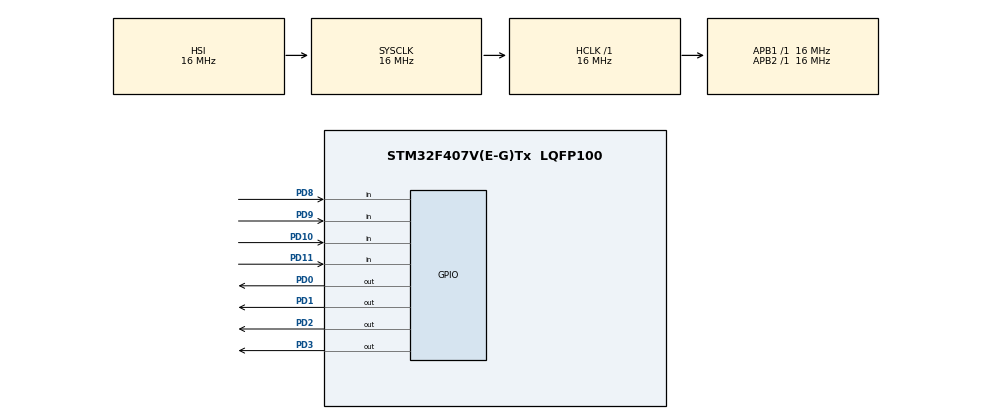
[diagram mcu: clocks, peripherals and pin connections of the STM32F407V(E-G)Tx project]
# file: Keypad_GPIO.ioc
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Mcu.Family=STM32F4
Mcu.Name=STM32F407V(E-G)Tx
Mcu.Package=LQFP100
NVIC.PriorityGroup=NVIC_PRIORITYGROUP_0
PD0.Signal=GPIO_Output
PD1.Signal=GPIO_Output
PD10.GPIO_PuPd=GPIO_PULLUP
PD10.Signal=GPIO_Input
PD11.GPIO_PuPd=GPIO_PULLUP
PD11.Signal=GPIO_Input
PD2.Signal=GPIO_Output
PD3.Signal=GPIO_Output
PD8.GPIO_PuPd=GPIO_PULLUP
PD8.Signal=GPIO_Input
PD9.GPIO_PuPd=GPIO_PULLUP
PD9.Signal=GPIO_Input
ProjectManager.HeapSize=0x200
ProjectManager.StackSize=0x400
ProjectManager.TargetToolchain=STM32CubeIDE
RCC.48MHZClocksFreq_Value=14285714.285714285
RCC.AHBFreq_Value=16000000
RCC.APB1Freq_Value=16000000
RCC.APB1TimFreq_Value=16000000
RCC.APB2Freq_Value=16000000
RCC.APB2TimFreq_Value=16000000
RCC.CortexFreq_Value=16000000
RCC.HCLKFreq_Value=16000000
RCC.HSE_VALUE=8000000
RCC.HSI_VALUE=16000000
RCC.LSE_VALUE=32768
RCC.PLLM=8
RCC.PLLN=50
RCC.PLLP=RCC_PLLP_DIV4
RCC.PLLQ=7
RCC.SYSCLKFreq_VALUE=16000000
RCC.VCOOutputFreq_Value=100000000
board=STM32F407G-DISC1

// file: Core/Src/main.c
/* USER CODE BEGIN Header */
/**
  ******************************************************************************
  * @file           : main.c
  * @brief          : Main program body
  ******************************************************************************
  * @attention
  *
  * Copyright (c) 2023 STMicroelectronics.
  * All rights reserved.
  *
  * This software is licensed under terms that can be found in the LICENSE file
  * in the root directory of this software component.
  * If no LICENSE file comes with this software, it is provided AS-IS.
  *
  ******************************************************************************
  */
/* USER CODE END Header */
#include "main.h"

/* USER CODE BEGIN Includes */
#include "keypad.h"
#include <stdio.h>
/* USER CODE END Includes */

/* USER CODE BEGIN PV */
uint8_t key = 0;
/* USER CODE END PV */

void SystemClock_Config(void);
static void MX_GPIO_Init(void);
/* USER CODE BEGIN PFP */

Keypad_HandleTypeDef keypad_init(void);

/* USER CODE END PFP */

int main(void)
{

  /* MCU Configuration--------------------------------------------------------*/

  /* Reset of all peripherals, Initializes the Flash interface and the Systick. */
  HAL_Init();

  /* Configure the system clock */
  SystemClock_Config();

  /* Initialize all configured peripherals */
  MX_GPIO_Init();
  /* USER CODE BEGIN 2 */

  Keypad_HandleTypeDef keypad = keypad_init();

  /* USER CODE END 2 */

  /* Infinite loop */
  /* USER CODE BEGIN WHILE */
  while (1)
  {

	  while(!key_selected(&keypad, &key));

    /* USER CODE END WHILE */

  }
}

void SystemClock_Config(void)
{
  RCC_OscInitTypeDef RCC_OscInitStruct = {0};
  RCC_ClkInitTypeDef RCC_ClkInitStruct = {0};

  /** Configure the main internal regulator output voltage
  */
  __HAL_RCC_PWR_CLK_ENABLE();
  __HAL_PWR_VOLTAGESCALING_CONFIG(PWR_REGULATOR_VOLTAGE_SCALE1);

  /** Initializes the RCC Oscillators according to the specified parameters
  * in the RCC_OscInitTypeDef structure.
  */
  RCC_OscInitStruct.OscillatorType = RCC_OSCILLATORTYPE_HSI;
  RCC_OscInitStruct.HSIState = RCC_HSI_ON;
  RCC_OscInitStruct.HSICalibrationValue = RCC_HSICALIBRATION_DEFAULT;
  RCC_OscInitStruct.PLL.PLLState = RCC_PLL_NONE;
  if (HAL_RCC_OscConfig(&RCC_OscInitStruct) != HAL_OK)
  {
    Error_Handler();
  }

  /** Initializes the CPU, AHB and APB buses clocks
  */
  RCC_ClkInitStruct.ClockType = RCC_CLOCKTYPE_HCLK|RCC_CLOCKTYPE_SYSCLK
                              |RCC_CLOCKTYPE_PCLK1|RCC_CLOCKTYPE_PCLK2;
  RCC_ClkInitStruct.SYSCLKSource = RCC_SYSCLKSOURCE_HSI;
  RCC_ClkInitStruct.AHBCLKDivider = RCC_SYSCLK_DIV1;
  RCC_ClkInitStruct.APB1CLKDivider = RCC_HCLK_DIV1;
  RCC_ClkInitStruct.APB2CLKDivider = RCC_HCLK_DIV1;

  if (HAL_RCC_ClockConfig(&RCC_ClkInitStruct, FLASH_LATENCY_0) != HAL_OK)
  {
    Error_Handler();
  }
}

static void MX_GPIO_Init(void)
{
  GPIO_InitTypeDef GPIO_InitStruct = {0};

  /* GPIO Ports Clock Enable */
  __HAL_RCC_GPIOD_CLK_ENABLE();

  /*Configure GPIO pin Output Level */
  HAL_GPIO_WritePin(GPIOD, GPIO_PIN_0|GPIO_PIN_1|GPIO_PIN_2|GPIO_PIN_3, GPIO_PIN_RESET);

  /*Configure GPIO pins : PD8 PD9 PD10 PD11 */
  GPIO_InitStruct.Pin = GPIO_PIN_8|GPIO_PIN_9|GPIO_PIN_10|GPIO_PIN_11;
  GPIO_InitStruct.Mode = GPIO_MODE_INPUT;
  GPIO_InitStruct.Pull = GPIO_PULLUP;
  HAL_GPIO_Init(GPIOD, &GPIO_InitStruct);

  /*Configure GPIO pins : PD0 PD1 PD2 PD3 */
  GPIO_InitStruct.Pin = GPIO_PIN_0|GPIO_PIN_1|GPIO_PIN_2|GPIO_PIN_3;
  GPIO_InitStruct.Mode = GPIO_MODE_OUTPUT_PP;
  GPIO_InitStruct.Pull = GPIO_NOPULL;
  GPIO_InitStruct.Speed = GPIO_SPEED_FREQ_LOW;
  HAL_GPIO_Init(GPIOD, &GPIO_InitStruct);

}

/* USER CODE BEGIN 4 */

Keypad_HandleTypeDef keypad_init(void){

    Keypad_HandleTypeDef keypad;

    Keypad_PinDef pin_columns[4] = {COLUMN_1_Pin, COLUMN_2_Pin, COLUMN_3_Pin, COLUMN_4_Pin};
    Keypad_PortDef port_columns[4] = { COLUMN_1_GPIO_Port, COLUMN_2_GPIO_Port, COLUMN_3_GPIO_Port, COLUMN_4_GPIO_Port };

    Keypad_PinDef pin_rows[4] = {ROW_1_Pin, ROW_2_Pin, ROW_3_Pin, ROW_4_Pin};
    Keypad_PortDef port_rows[4] = { ROW_1_GPIO_Port, ROW_2_GPIO_Port, ROW_3_GPIO_Port, ROW_4_GPIO_Port };

    keypad = keypad_create(pin_rows, port_rows, pin_columns, port_columns);

    return keypad;

}

/* USER CODE END 4 */

void Error_Handler(void)
{
  __disable_irq();
  while (1)
  {
  }
}
